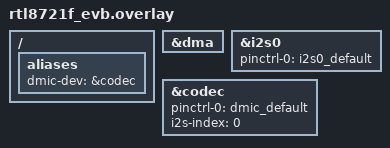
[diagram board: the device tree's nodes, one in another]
/*
 * Copyright (c) 2026 Realtek Semiconductor Corp.
 *
 * SPDX-License-Identifier: Apache-2.0
 */

/ {
	aliases {
		dmic-dev = &codec;
	};
};

&dma {
	status = "okay";
};

&i2s0 {
	pinctrl-0 = <&i2s0_default>;
	pinctrl-names = "default";
	status = "okay";
};

&codec {
	pinctrl-0 = <&dmic_default>;
	pinctrl-names = "default";
	i2s-index = <0>;
	status = "okay";
};
